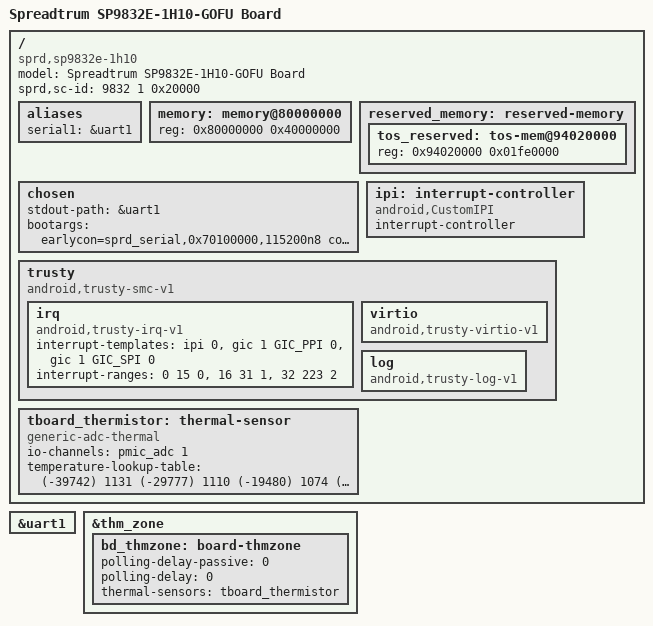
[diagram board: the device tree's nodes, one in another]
/*
 * Spreadtrum SP9832E 1H10 GO FULL board DTS file
 *
 * Copyright (C) 2019-2020, Spreadtrum Communications Inc.
 *
 * This file is licensed under a dual GPLv2 or X11 license.
 */
/dts-v1/;

#include "sc9832e.dtsi"
#include "sp9832e-go-mach.dtsi"
#include "sc2721.dtsi"

/ {
	model = "Spreadtrum SP9832E-1H10-GOFU Board";

	compatible = "sprd,sp9832e-1h10", "sprd,sc9832e";

	sprd,sc-id = <9832 1 0x20000>;

	aliases {
		serial1 = &uart1;
	};

	memory: memory@80000000 {
		device_type = "memory";
		reg = <0x80000000 0x40000000>;
	};

	reserved_memory: reserved-memory {
		tos_reserved: tos-mem@94020000{
			reg = <0x94020000 0x01fe0000>;
		};

	};

	chosen {
		stdout-path = &uart1;
		bootargs = "earlycon=sprd_serial,0x70100000,115200n8 console=ttyS1,115200n8 loglevel=11 init=/init root=/dev/ram0 rw androidboot.hardware=sp9832e_1h10_go vmalloc=360M androidboot.dtbo_idx=0 androidboot.selinux=permissive printk.devkmsg=on androidboot.boot_devices=soc/soc:ap-ahb/20600000.sdio";
	};

	ipi: interrupt-controller {
		compatible = "android,CustomIPI";
		#interrupt-cells = <1>;
		interrupt-controller;
	};

	trusty {
		compatible = "android,trusty-smc-v1";

		irq {
			compatible = "android,trusty-irq-v1";
			interrupt-templates = <&ipi 0>,
						<&gic 1 GIC_PPI 0>,
						<&gic 1 GIC_SPI 0>;
			interrupt-ranges = < 0  15 0>,
						<16  31 1>,
						<32 223 2>;
		};

		virtio {
			compatible = "android,trusty-virtio-v1";
		};

		log {
			compatible = "android,trusty-log-v1";
		};
	};

	tboard_thermistor:thermal-sensor {
		compatible = "generic-adc-thermal";
		#thermal-sensor-cells = <0>;
		io-channels = <&pmic_adc 1>;
		io-channel-names = "sensor-channel";
		temperature-lookup-table = <	(-39742) 1131
						(-29777) 1110
						(-19480) 1074
						(-4679) 983
						10110 838
						24805 654
						44922 413
						54903 316
						64895 238
						74884 178
						84883 133
						94883 100
						104880 75
						114889 57
						124872 43 >;
	};
};

&uart1 {
	status = "okay";
};

&thm_zone {
	bd_thmzone: board-thmzone {
		polling-delay-passive = <0>;
		polling-delay = <0>;
		thermal-sensors = <&tboard_thermistor>;
	};
};
